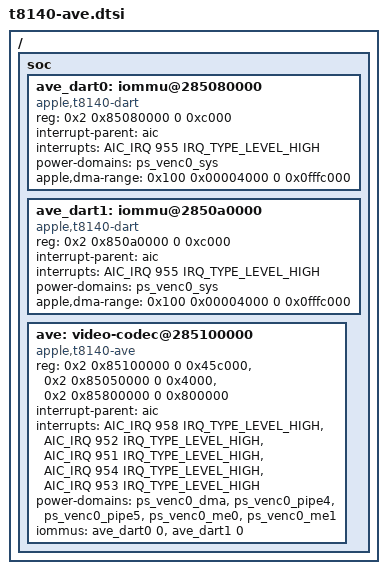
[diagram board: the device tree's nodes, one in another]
// SPDX-License-Identifier: GPL-2.0+ OR MIT
/* Experimental supplement to the pinned J700 DT, based on its live ADT.
 * Only AVE/DART connections are added. Keep all encoder engines powered
 * while the experimental firmware driver holds live buffers.
 */
/ {
	soc {
		ave_dart0: iommu@285080000 {
			compatible = "apple,t8140-dart", "apple,t8110-dart";
			reg = <0x2 0x85080000 0 0xc000>;
			interrupt-parent = <&aic>;
			interrupts = <AIC_IRQ 955 IRQ_TYPE_LEVEL_HIGH>;
			power-domains = <&ps_venc0_sys>;
			#iommu-cells = <1>;
			/* First 256 MiB of the ADT 1 TiB-based aperture, excluding page 0. */
			apple,dma-range = <0x100 0x00004000 0 0x0fffc000>;
		};

		ave_dart1: iommu@2850a0000 {
			compatible = "apple,t8140-dart", "apple,t8110-dart";
			reg = <0x2 0x850a0000 0 0xc000>;
			interrupt-parent = <&aic>;
			interrupts = <AIC_IRQ 955 IRQ_TYPE_LEVEL_HIGH>;
			power-domains = <&ps_venc0_sys>;
			#iommu-cells = <1>;
			apple,dma-range = <0x100 0x00004000 0 0x0fffc000>;
		};

		ave: video-codec@285100000 {
			compatible = "apple,t8140-ave";
			reg = <0x2 0x85100000 0 0x45c000>,
			      <0x2 0x85050000 0 0x4000>,
			      <0x2 0x85800000 0 0x800000>;
			reg-names = "codec", "mailbox", "coproc";
			interrupt-parent = <&aic>;
			interrupts = <AIC_IRQ 958 IRQ_TYPE_LEVEL_HIGH>,
				     <AIC_IRQ 952 IRQ_TYPE_LEVEL_HIGH>,
				     <AIC_IRQ 951 IRQ_TYPE_LEVEL_HIGH>,
				     <AIC_IRQ 954 IRQ_TYPE_LEVEL_HIGH>,
				     <AIC_IRQ 953 IRQ_TYPE_LEVEL_HIGH>;
			power-domains = <&ps_venc0_dma>, <&ps_venc0_pipe4>,
				       <&ps_venc0_pipe5>, <&ps_venc0_me0>, <&ps_venc0_me1>;
			power-domain-names = "dma", "pipe4", "pipe5", "me0", "me1";
			iommus = <&ave_dart0 0>, <&ave_dart1 0>;
		};
	};
};
